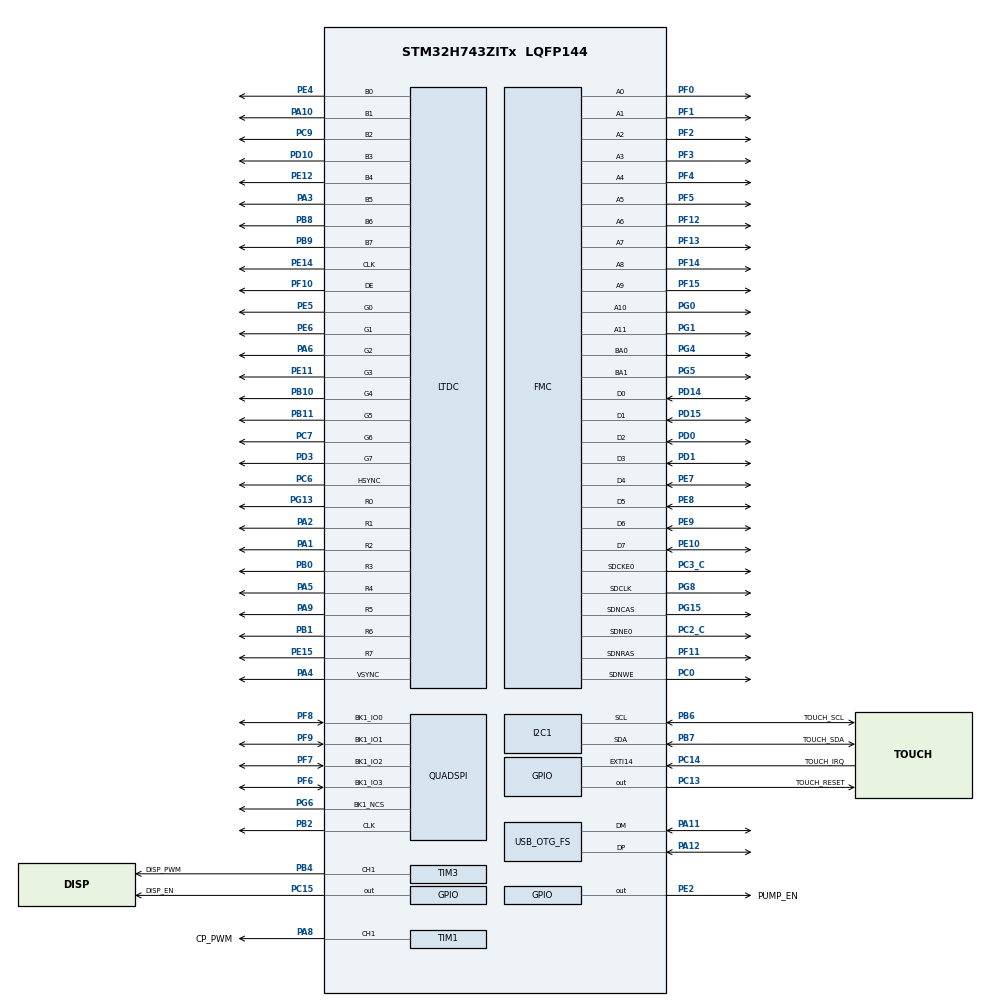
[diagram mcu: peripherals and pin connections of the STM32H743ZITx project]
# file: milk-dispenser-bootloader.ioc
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SH.FMC_D7_DA7.0=FMC_D7,sd-8b-d1
PE14.GPIO_Speed=GPIO_SPEED_FREQ_VERY_HIGH
FMC.RCDDelay1=2
FMC.SDClockPeriod1=FMC_SDRAM_CLOCK_PERIOD_2
SH.FMC_A0.0=FMC_A0,12b-sda1
QUADSPI.ClockPrescaler=7
PB10.Mode=RGB888
PG4.Signal=FMC_A14_BA0
PG8.Signal=FMC_SDCLK
I2C1.I2C_Rise_Time=14
PG0.Signal=FMC_A10
RCC.PLLFRACN=0
PB7.GPIO_FM7=SYSCFG_PMCR_I2C_PB7_FMP
PC3_C.Mode=SdramChipSelect1_1
FMC.LoadToActiveDelay1=2
CORTEX_M7.AccessPermission-Cortex_Memory_Protection_Unit_Region2_Settings=MPU_REGION_FULL_ACCESS
PB6.GPIO_Label=TOUCH_SCL
SH.FMC_D5_DA5.0=FMC_D5,sd-8b-d1
PA3.GPIO_Speed=GPIO_SPEED_FREQ_VERY_HIGH
PD3.GPIO_Speed=GPIO_SPEED_FREQ_VERY_HIGH
PG6.Mode=Single Bank 1
PG13.Signal=LTDC_R0
LTDC.Red=0
RCC.SYSCLKSource=RCC_SYSCLKSOURCE_PLLCLK
PB11.GPIO_Speed=GPIO_SPEED_FREQ_VERY_HIGH
SH.FMC_A15_BA1.0=FMC_BA1,FourSdramBanks1
PA14\ (JTCK/SWCLK).Signal=DEBUG_JTCK-SWCLK
CORTEX_M7.Enable-Cortex_Memory_Protection_Unit_Region0_Settings=MPU_REGION_ENABLE
CORTEX_M7.IsBufferable-Cortex_Memory_Protection_Unit_Region1_Settings=MPU_ACCESS_BUFFERABLE
PA4.Mode=RGB888
PF7.Signal=QUADSPI_BK1_IO2
SH.FMC_SDNWE.0=FMC_SDNWE,12b-sda1
PB6.Signal=I2C1_SCL
PC7.Signal=LTDC_G6
PB6.Mode=I2C
PD0.Signal=FMC_D2_DA2
USB_DEVICE.MSC_MEDIA_PACKET-MSC_FS=4096
PE5.Signal=LTDC_G0
QUADSPI.FlashSize=22
NVIC.EXTI15_10_IRQn=true\:2\:0\:true\:false\:true\:true\:true
PB2.Signal=QUADSPI_CLK
RCC.I2C123CLockSelection=RCC_I2C123CLKSOURCE_HSI
RCC.DIVM3=3
RCC.DIVM2=3
RCC.DIVM1=2
FATFS._USE_STRFUNC=0
FMC.SelfRefreshTime1=5
LTDC.PixelFormat_L0=LTDC_PIXEL_FORMAT_RGB565
TIM1.Channel-PWM\ Generation1\ CH1=TIM_CHANNEL_1
PB1.GPIO_Speed=GPIO_SPEED_FREQ_VERY_HIGH
PE9.Signal=FMC_D6_DA6
SH.FMC_A2.0=FMC_A2,12b-sda1
PC9.Mode=RGB888
FATFS._USE_MKFS=0
PE2.Signal=GPIO_Output
PF8.Mode=Single Bank 1
PA8.Signal=S_TIM1_CH1
PA14\ (JTCK/SWCLK).Mode=Serial_Wire
SH.FMC_D1_DA1.0=FMC_D1,sd-8b-d1
PF3.Signal=FMC_A3
PD3.Mode=RGB888
PE10.Signal=FMC_D7_DA7
LTDC.HSync=30
RCC.CKPERSourceSelection=RCC_CLKPSOURCE_CSI
CORTEX_M7.DisableExec-Cortex_Memory_Protection_Unit_Region1_Settings=MPU_INSTRUCTION_ACCESS_ENABLE
Mcu.Package=LQFP144
PB9.Signal=LTDC_B7
PB1.Signal=LTDC_R6
RCC.PLL3FRACN=0
PB6.GPIO_FM6=SYSCFG_PMCR_I2C_PB6_FMP
LTDC.Green=0
PA10.Signal=LTDC_B1
FMC.WriteRecoveryTime1=3
PE12.GPIO_Speed=GPIO_SPEED_FREQ_VERY_HIGH
SH.FMC_A1.0=FMC_A1,12b-sda1
FATFS._FS_MINIMIZE=0
SH.FMC_SDCLK.0=FMC_SDCLK,12b-sda1
LTDC.VSync=10
RCC.APB4Freq_Value=120000000
PF14.Signal=FMC_A8
CORTEX_M7.Enable-Cortex_Memory_Protection_Unit_Region1_Settings=MPU_REGION_ENABLE
FMC.RowCycleDelay2=6
PF10.Mode=RGB888
VP_USB_DEVICE_VS_USB_DEVICE_MSC_FS.Mode=MSC_FS
FMC.RowCycleDelay1=6
PA6.GPIO_Speed=GPIO_SPEED_FREQ_VERY_HIGH
FMC.ColumnBitsNumber1=FMC_SDRAM_COLUMN_BITS_NUM_10
PE6.GPIO_Speed=GPIO_SPEED_FREQ_VERY_HIGH
PH0-OSC_IN\ (PH0).Mode=HSE-External-Oscillator
PC6.GPIO_Speed=GPIO_SPEED_FREQ_VERY_HIGH
PA8.GPIO_Speed=GPIO_SPEED_FREQ_VERY_HIGH
PD15.Signal=FMC_D1_DA1
SH.FMC_D3_DA3.0=FMC_D3,sd-8b-d1
CORTEX_M7.IsBufferable-Cortex_Memory_Protection_Unit_Region0_Settings=MPU_ACCESS_NOT_BUFFERABLE
FATFS._MIN_SS=4096
PG6.GPIO_Speed=GPIO_SPEED_FREQ_VERY_HIGH
PA5.Mode=RGB888
PE12.Mode=RGB888
PB7.GPIO_PuPd=GPIO_PULLUP
SH.FMC_A4.0=FMC_A4,12b-sda1
I2C1.I2C_Fall_Time=14
PE11.GPIO_Speed=GPIO_SPEED_FREQ_VERY_HIGH
PG5.Signal=FMC_A15_BA1
PC13.Signal=GPIO_Output
PB6.GPIO_PuPd=GPIO_PULLUP
PD3.Signal=LTDC_G7
CORTEX_M7.IsCacheable-Cortex_Memory_Protection_Unit_Region0_Settings=MPU_ACCESS_NOT_CACHEABLE
PC6.Signal=LTDC_HSYNC
PD1.Signal=FMC_D3_DA3
PC0.Signal=FMC_SDNWE
LTDC.ImageWidth_L0=800
PD10.Signal=LTDC_B3
PA3.Mode=RGB888
SH.FMC_A3.0=FMC_A3,12b-sda1
PA8.GPIO_Label=CP_PWM
FMC.CASLatency1=FMC_SDRAM_CAS_LATENCY_2
TIM3.Pulse-PWM\ Generation1\ CH1=922
PB11.Mode=RGB888
PC6.Mode=RGB888
PA9.Signal=LTDC_R5
RCC.DIVN3=20
RCC.DIVN2=60
I2C1.Timing=0x108083B5
RCC.DIVN1=64
PC2_C.Mode=SdramChipSelect1_1
CORTEX_M7.BaseAddress-Cortex_Memory_Protection_Unit_Region0_Settings=0x60000000
PB10.Signal=LTDC_G4
RCC.USBCLockSelection=RCC_USBCLKSOURCE_HSI48
PA5.Signal=LTDC_R4
CORTEX_M7.Enable-Cortex_Memory_Protection_Unit_Region2_Settings=MPU_REGION_ENABLE
FMC.ReadBurst1=FMC_SDRAM_RBURST_ENABLE
SH.FMC_A6.0=FMC_A6,12b-sda1
FMC.ReadBurst2=FMC_SDRAM_RBURST_ENABLE
PA1.Mode=RGB888
PE14.Signal=LTDC_CLK
PE6.Mode=RGB888
PE15.Signal=LTDC_R7
PE8.Signal=FMC_D5_DA5
RCC.FMCCLockSelection=RCC_FMCCLKSOURCE_PLL2
CORTEX_M7.AccessPermission-Cortex_Memory_Protection_Unit_Region0_Settings=MPU_REGION_FULL_ACCESS
QUADSPI.FifoThreshold=5
PF13.Signal=FMC_A7
SH.FMC_SDNCAS.0=FMC_SDNCAS,12b-sda1
RCC.ProductRev=revV
PA4.Signal=LTDC_VSYNC
PC14-OSC32_IN\ (OSC32_IN).GPIO_Label=TOUCH_IRQ
SH.FMC_A5.0=FMC_A5,12b-sda1
LTDC.Alpha_L0=255
PA11.Signal=USB_OTG_FS_DM
ProjectManager.HeapSize=0x2000
PB1.Mode=RGB888
PF6.Mode=Single Bank 1
PF9.Signal=QUADSPI_BK1_IO1
CORTEX_M7.DisableExec-Cortex_Memory_Protection_Unit_Region2_Settings=MPU_INSTRUCTION_ACCESS_DISABLE
PC9.GPIO_Speed=GPIO_SPEED_FREQ_VERY_HIGH
NVIC.PriorityGroup=NVIC_PRIORITYGROUP_4
PE15.GPIO_Speed=GPIO_SPEED_FREQ_VERY_HIGH
PB8.Mode=RGB888
PF4.Signal=FMC_A4
PB4\ (NJTRST).GPIO_Label=DISP_PWM
PB6.GPIO_Speed=GPIO_SPEED_FREQ_VERY_HIGH
RCC.DIVR3=10
RCC.DIVR2=3
PB0.Signal=LTDC_R3
LTDC.Alpha0_L0=0
PA13\ (JTMS/SWDIO).Signal=DEBUG_JTMS-SWDIO
PE15.Mode=RGB888
PF6.GPIO_Speed=GPIO_SPEED_FREQ_VERY_HIGH
Mcu.Family=STM32H7
LTDC.BlendingFactor1_L0=LTDC_BLENDING_FACTOR1_PAxCA
PA6.Mode=RGB888
USB_DEVICE.CLASS_NAME_FS=MSC
SH.FMC_A8.0=FMC_A8,12b-sda1
RCC.CortexFreq_Value=480000000
PG6.Signal=QUADSPI_BK1_NCS
PB10.GPIO_Speed=GPIO_SPEED_FREQ_VERY_HIGH
RCC.HPRE=RCC_HCLK_DIV2
PH0-OSC_IN\ (PH0).Signal=RCC_OSC_IN
LTDC.HBP=46
PB2.GPIO_Speed=GPIO_SPEED_FREQ_VERY_HIGH
SH.FMC_NBL0.0=FMC_NBL0
PA2.GPIO_Speed=GPIO_SPEED_FREQ_VERY_HIGH
SH.FMC_D6_DA6.0=FMC_D6,sd-8b-d1
PA11.Mode=Device_Only
PF9.GPIO_Speed=GPIO_SPEED_FREQ_VERY_HIGH
PB4\ (NJTRST).GPIO_Speed=GPIO_SPEED_FREQ_HIGH
RCC.PLL2FRACN=0
SH.FMC_A14_BA0.0=FMC_BA0,FourSdramBanks1
TIM1.Pulse-PWM\ Generation1\ CH1=32768
SH.FMC_A11.0=FMC_A11,12b-sda1
PC13.GPIO_Label=TOUCH_RESET
PB11.Signal=LTDC_G5
LTDC.PCPolarity=LTDC_PCPOLARITY_IIPC
PG15.Signal=FMC_SDNCAS
ProjectManager.StackSize=0x4000
SH.FMC_A7.0=FMC_A7,12b-sda1
PA12.Signal=USB_OTG_FS_DP
PE11.Mode=RGB888
LTDC.Blue=0
FMC.BankMapConfig=FMC_SWAPBMAP_SDRAM_SRAM
RCC.HCLKFreq_Value=240000000
TIM3.Period=1025
LTDC.WindowX1_L0=800
PF12.Signal=FMC_A6
PD10.Mode=RGB888
PC2_C.Signal=FMC_SDNE0
SH.FMC_A10.0=FMC_A10,12b-sda1
TIM3.Channel-PWM\ Generation1\ CH1=TIM_CHANNEL_1
PH1-OSC_OUT\ (PH1).Mode=HSE-External-Oscillator
RCC.HSE_VALUE=30000000
CORTEX_M7.Size-Cortex_Memory_Protection_Unit_Region2_Settings=MPU_REGION_SIZE_4KB
FMC.ExitSelfRefreshDelay1=8
FMC.RPDelay2=2
FMC.RPDelay1=2
PA4.GPIO_Speed=GPIO_SPEED_FREQ_VERY_HIGH
SH.FMC_D2_DA2.0=FMC_D2,sd-8b-d1
LTDC.VBP=23
PF9.Mode=Single Bank 1
PF7.GPIO_Speed=GPIO_SPEED_FREQ_VERY_HIGH
PE4.GPIO_Speed=GPIO_SPEED_FREQ_VERY_HIGH
PF11.Signal=FMC_SDNRAS
PC13.GPIO_PuPd=GPIO_PULLUP
LTDC.HFP=4
PB7.Signal=I2C1_SDA
LTDC.BlendingFactor2_L0=LTDC_BLENDING_FACTOR2_PAxCA
PG13.Mode=RGB888
FMC.ReadPipeDelay1=FMC_SDRAM_RPIPE_DELAY_0
PE4.Mode=RGB888
SH.S_TIM3_CH1.0=TIM3_CH1,PWM Generation1 CH1
PD10.GPIO_Speed=GPIO_SPEED_FREQ_VERY_HIGH
SH.FMC_SDNRAS.0=FMC_SDNRAS,12b-sda1
LTDC.ActiveW=800
PE4.Signal=LTDC_B0
CORTEX_M7.DisableExec-Cortex_Memory_Protection_Unit_Region0_Settings=MPU_INSTRUCTION_ACCESS_DISABLE
RCC.APB3Freq_Value=120000000
PB7.GPIO_Label=TOUCH_SDA
PA6.Signal=LTDC_G2
SH.FMC_D0_DA0.0=FMC_D0,sd-8b-d1
RCC.D1PPRE=RCC_APB3_DIV2
CORTEX_M7.BaseAddress-Cortex_Memory_Protection_Unit_Region1_Settings=0x30000000
RCC.EnbaleCSS=true
NVIC.OTG_FS_IRQn=true\:0\:0\:false\:false\:true\:false\:true
USB_OTG_FS.VirtualMode=Device_Only
SH.FMC_A9.0=FMC_A9,12b-sda1
PF8.Signal=QUADSPI_BK1_IO0
SH.FMC_D4_DA4.0=FMC_D4,sd-8b-d1
PF5.Signal=FMC_A5
PA10.GPIO_Speed=GPIO_SPEED_FREQ_VERY_HIGH
CORTEX_M7.Size-Cortex_Memory_Protection_Unit_Region1_Settings=MPU_REGION_SIZE_256KB
FATFS._FS_LOCK=0
PB9.GPIO_Speed=GPIO_SPEED_FREQ_VERY_HIGH
PG13.GPIO_Speed=GPIO_SPEED_FREQ_VERY_HIGH
PF0.Signal=FMC_A0
PE7.Signal=FMC_D4_DA4
CORTEX_M7.IsShareable-Cortex_Memory_Protection_Unit_Region1_Settings=MPU_ACCESS_SHAREABLE
PE2.GPIO_Label=PUMP_EN
VP_TIM3_VS_ClockSourceINT.Mode=Internal
PC13.PinState=GPIO_PIN_RESET
PA3.Signal=LTDC_B5
PB7.GPIO_Speed=GPIO_SPEED_FREQ_VERY_HIGH
RCC.PLLSourceVirtual=RCC_PLLSOURCE_HSE
I2C1.Speed=100
QUADSPI.ChipSelectHighTime=QSPI_CS_HIGH_TIME_2_CYCLE
USB_DEVICE.VirtualMode-MSC_FS=Msc
CORTEX_M7.CPU_ICache=Enabled
LTDC.VFP=22
LTDC.WindowY1_L0=480
PA13\ (JTMS/SWDIO).Mode=Serial_Wire
PA10.Mode=RGB888
USB_DEVICE.VirtualModeFS=Msc_FS
PG1.Signal=FMC_A11
PF10.GPIO_Speed=GPIO_SPEED_FREQ_VERY_HIGH
RCC.D2PPRE2=RCC_APB2_DIV2
RCC.D2PPRE1=RCC_APB1_DIV2
CORTEX_M7.BaseAddress-Cortex_Memory_Protection_Unit_Region2_Settings=0x38800000
PH1-OSC_OUT\ (PH1).Signal=RCC_OSC_OUT
PB0.GPIO_Speed=GPIO_SPEED_FREQ_VERY_HIGH
PF7.Mode=Single Bank 1
CORTEX_M7.MPU_Control=MPU_PRIVILEGED_DEFAULT
PA9.Mode=RGB888
SH.S_TIM1_CH1.0=TIM1_CH1,PWM Generation1 CH1
PF6.Signal=QUADSPI_BK1_IO3
ProjectManager.TargetToolchain=STM32CubeIDE
PC15-OSC32_OUT\ (OSC32_OUT).Signal=GPIO_Output
PB9.Mode=RGB888
PF2.Signal=FMC_A2
RCC.USBFreq_Value=48000000
PE11.Signal=LTDC_G3
PA1.Signal=LTDC_R2
VP_FATFS_VS_Generic.Mode=User_defined
PB0.Mode=RGB888
board=custom
PC7.GPIO_Speed=GPIO_SPEED_FREQ_VERY_HIGH
FATFS._USE_FASTSEEK=0
RCC.APB2Freq_Value=120000000
LTDC.Layers=0
PF10.Signal=LTDC_DE
PA1.GPIO_Speed=GPIO_SPEED_FREQ_VERY_HIGH
PE14.Mode=RGB888
PE5.Mode=RGB888
CORTEX_M7.IsShareable-Cortex_Memory_Protection_Unit_Region0_Settings=MPU_ACCESS_SHAREABLE
RCC.ADCFreq_Value=300000000
PF15.Signal=FMC_A9
PF1.Signal=FMC_A1
PE6.Signal=LTDC_G1
Mcu.Name=STM32H743ZITx
PE0.Signal=FMC_NBL0
CORTEX_M7.Size-Cortex_Memory_Protection_Unit_Region0_Settings=MPU_REGION_SIZE_16MB
PE12.Signal=LTDC_B4
PA2.Signal=LTDC_R1
CORTEX_M7.AccessPermission-Cortex_Memory_Protection_Unit_Region1_Settings=MPU_REGION_FULL_ACCESS
CORTEX_M7.IsCacheable-Cortex_Memory_Protection_Unit_Region1_Settings=MPU_ACCESS_CACHEABLE
FATFS._MAX_SS=4096
PD14.Signal=FMC_D0_DA0
LTDC.WindowY0_L0=0
RCC.SYSCLKFreq_VALUE=480000000
PA12.Mode=Device_Only
LTDC.WindowX0_L0=0
PC14-OSC32_IN\ (OSC32_IN).Signal=GPXTI14
PC15-OSC32_OUT\ (OSC32_OUT).GPIO_Label=DISP_EN
PB2.Mode=Single Bank 1
PB7.Mode=I2C
PA5.GPIO_Speed=GPIO_SPEED_FREQ_VERY_HIGH
PC3_C.Signal=FMC_SDCKE0
PF8.GPIO_Speed=GPIO_SPEED_FREQ_VERY_HIGH
PE5.GPIO_Speed=GPIO_SPEED_FREQ_VERY_HIGH
PA2.Mode=RGB888
PA9.GPIO_Speed=GPIO_SPEED_FREQ_VERY_HIGH
PB8.Signal=LTDC_B6
RCC.D3PPRE=RCC_APB4_DIV2
FATFS._FS_READONLY=0
PC9.Signal=LTDC_B2
CORTEX_M7.CPU_DCache=Enabled
PC7.Mode=RGB888
RCC.APB1Freq_Value=120000000
PB8.GPIO_Speed=GPIO_SPEED_FREQ_VERY_HIGH
LTDC.ImageHeight_L0=480
PB4\ (NJTRST).Signal=S_TIM3_CH1

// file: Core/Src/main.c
/* USER CODE BEGIN Header */
/**
 ******************************************************************************
 * @file           : main.c
 * @brief          : Main program body
 ******************************************************************************
 * @attention
 *
 * <h2><center>&copy; Copyright (c) 2020 STMicroelectronics.
 * All rights reserved.</center></h2>
 *
 * This software component is licensed by ST under BSD 3-Clause license,
 * the "License"; You may not use this file except in compliance with the
 * License. You may obtain a copy of the License at:
 *                        opensource.org/licenses/BSD-3-Clause
 *
 ******************************************************************************
 */
/* USER CODE END Header */
#include "main.h"
#include "fatfs.h"
#include "i2c.h"
#include "ltdc.h"
#include "quadspi.h"
#include "tim.h"
#include "usb_device.h"
#include "gpio.h"
#include "fmc.h"

/* USER CODE BEGIN Includes */
#include <stdio.h>
#include <string.h>
#include <usbd_core.h>
#include "apploader.h"
#include "config.h"
#include "gt911.h"
#include "int_flash.h"
#include "log.h"
#include "pump.h"
#include "pump_power.h"
#include "sst26_flash.h"
#include "tft.h"
#include "terminal.h"

/* USER CODE END Includes */

/* USER CODE BEGIN PD */

#define MAGIC_CONST (uint32_t)0xA5B6C7E8
#define BackupRAM_BASE 0x38800000

/* USER CODE END PD */

/* USER CODE BEGIN PV */
extern USBD_HandleTypeDef hUsbDeviceFS;

extern uint32_t _aisr;
/* USER CODE END PV */

void SystemClock_Config(void);
static void MPU_Config(void);

/* USER CODE BEGIN 0 */

void printHex(const char *prefix, size_t length, uint8_t *buffer) {
	printf(prefix);
	for (size_t i = 0; i < length; i++) {
		if (i > 0) {
			if (i % 8 == 0) {
				printf("\n");
			} else {
				printf(" ");
			}
		}
		printf("0x%02X", buffer[i]);
	}
	printf("\n");
}

void enableBackupRAM() {
	HAL_PWREx_ConfigSupply(PWR_LDO_SUPPLY);
	HAL_PWR_EnableBkUpAccess();
	__HAL_RCC_BKPRAM_CLK_ENABLE();
	volatile uint32_t i = 0xffff;
	while (i != 0)
		i--;
}

/* USER CODE END 0 */

int main(void)
{
  /* USER CODE BEGIN 1 */
//	SCB->VTOR = (uint32_t)(&_aisr);
	SCB->VTOR = (uint32_t)(0x30000000);

	enableBackupRAM();

	__IO uint32_t *load_app_flag = (__IO uint32_t*)(BackupRAM_BASE);

	if (*load_app_flag == MAGIC_CONST) {
		*load_app_flag = (uint32_t) 0;
		AppLoader_load_application();
	}

	HAL_StatusTypeDef status = HAL_ERROR;

  /* USER CODE END 1 */

  /* MPU Configuration--------------------------------------------------------*/
  MPU_Config();

  /* Enable I-Cache---------------------------------------------------------*/
  SCB_EnableICache();

  /* Enable D-Cache---------------------------------------------------------*/
  SCB_EnableDCache();

  /* MCU Configuration--------------------------------------------------------*/

  /* Reset of all peripherals, Initializes the Flash interface and the Systick. */
  HAL_Init();

  /* Configure the system clock */
  SystemClock_Config();

  /* Initialize all configured peripherals */
  MX_GPIO_Init();
  MX_LTDC_Init();
  MX_TIM3_Init();
  MX_FMC_Init();
  MX_I2C1_Init();
  MX_TIM1_Init();
  MX_QUADSPI_Init();
  MX_USB_DEVICE_Init();
  MX_FATFS_Init();
  /* USER CODE BEGIN 2 */
	USBD_Stop(&hUsbDeviceFS);

	struct tTftFramebuffer framebuffer = TFT_init_framebuffer(&hltdc);
	terminal_init(&framebuffer);

	TFT_Set_brightness(256);

	HAL_GPIO_WritePin(DISP_EN_GPIO_Port, DISP_EN_Pin, GPIO_PIN_RESET);
	HAL_Delay(100);
	HAL_GPIO_WritePin(DISP_EN_GPIO_Port, DISP_EN_Pin, GPIO_PIN_SET);
	HAL_Delay(100);

	log_debug("Debug log");
	log_info("Info log");
	log_warn("Warn log");
	log_error("Error log");

	SST26_config.hqspi = &hqspi;
	SST26_config.timeout = 1000;

	status = SST26_init();
	if (status != HAL_OK) {
		log_error("Cannot initialize SST26 chip (external flash): 0x%02X",
				status);
		Error_Handler();
	}

	gt911_irq = false;
	if (GT911_Init() != HAL_OK) {
		printf("Touch init error. Reset the device\n");
		while (1)
			;
	}
	HAL_Delay(100);
	gt911_irq = true;

	FATFS FatFs;
	FRESULT FatResult;

	FatResult = f_mount(&FatFs, "", 1);
	if (FatResult != FR_OK) {
		log_error("f_mount error: 0x%02X", FatResult);
		Error_Handler();
	}
	struct tBootloaderConfig *config = BtldrConfig_Get();
	log_info("Touch the screen within %d seconds to activate flash drive",
			config->wait_for_flash_activation_confirmation_ms / 1000);
	uint32_t timeout_at = HAL_GetTick()
			+ config->wait_for_flash_activation_confirmation_ms;
	uint32_t printAt = HAL_GetTick() + 1000;
	while (HAL_GetTick() < timeout_at) {
		if (gt911.TouchCount > 0) {
			log_info("Activating flash drive in %d seconds",
					config->activate_flash_drive_timeout_ms / 1000);
			log_info("Reboot device when finished");
			HAL_Delay(config->activate_flash_drive_timeout_ms);
			f_mount(NULL, "", 1);
			USBD_Start(&hUsbDeviceFS);
			while (1)
				;
		}
		if (HAL_GetTick() > printAt) {
			printAt = HAL_GetTick() + 1000;
			log_info("%ld  ", (timeout_at - HAL_GetTick()) / 1000);
		}
	}
	log_info(
			"Bootloader was not activated. Running main application in %d seconds",
			config->activate_main_program_timeout_ms / 1000);
	HAL_Delay(config->activate_main_program_timeout_ms);

	log_info("This is run #%llu", BtldrConfig_incrementRuns());

	log_info("listing files in root");
	DIR dir;
	FatResult = f_opendir(&dir, "/");
	if (FatResult != FR_OK) {
		log_error("f_opendir error: 0x%02X", FatResult);
		Error_Handler();
	}

	FILINFO fileinfo;
	for (;;) {
		FatResult = f_readdir(&dir, &fileinfo);
		if (FatResult != FR_OK) {
			log_error("f_readdir error: 0x%02X", FatResult);
			Error_Handler();
		}
		if (strlen(fileinfo.fname) == 0) {
			break;
		}

		log_info("%c------ %-10lu %s", ((fileinfo.fattrib & AM_DIR) ? 'd':' '),
				fileinfo.fsize, fileinfo.fname);

	}

	f_closedir(&dir);

	log_info("Checking firmware");
	enum APL_RES aplres = AppLoader_check_firmware();
	switch (aplres) {
	case APPLOADER_OK:
	default:
		break;
	case APPLOADER_NO_FIRMWARE:
		log_error("Application firmware not found: APP.BIN");
		break;
	case APPLOADER_NO_CRC_FILE:
		log_error("Application checksum not found: APP.CRC");
		break;
	case APPLOADER_CRC_MISMATCH:
		log_error("Application checksum mismatch: APP.BIN <-> APP.CRC");
		break;
	}

	if (APPLOADER_OK == aplres) {
		log_info("New firmware check ok: code 0x%02X", aplres);
		log_info("Updating firmware...");
		if (!AppLoader_update_firmware()) {
			log_error("Firmware update failed");
			Error_Handler();
		}
		log_info("Verifying...");
		if (!AppLoader_verify_firmware()) {
			log_error("Firmware verification failed!");
			Error_Handler();
		}
	}

	// Deinit what we can
	f_mount(NULL, "", 1);

	log_info("Loading application...");
	*load_app_flag = MAGIC_CONST;
	HAL_Delay(1000);
	NVIC_SystemReset();

  /* USER CODE END 2 */

  /* Infinite loop */
  /* USER CODE BEGIN WHILE */
	while (1) {
		HAL_Delay(100000);
		printf("[%8ld] Hello, world!\n", HAL_GetTick());
    /* USER CODE END WHILE */

	}
}

void SystemClock_Config(void)
{
  RCC_OscInitTypeDef RCC_OscInitStruct = {0};
  RCC_ClkInitTypeDef RCC_ClkInitStruct = {0};

  /** Supply configuration update enable
  */
  HAL_PWREx_ConfigSupply(PWR_LDO_SUPPLY);
  /** Configure the main internal regulator output voltage
  */
  __HAL_PWR_VOLTAGESCALING_CONFIG(PWR_REGULATOR_VOLTAGE_SCALE0);

  while(!__HAL_PWR_GET_FLAG(PWR_FLAG_VOSRDY)) {}
  /** Macro to configure the PLL clock source
  */
  __HAL_RCC_PLL_PLLSOURCE_CONFIG(RCC_PLLSOURCE_HSE);
  /** Initializes the RCC Oscillators according to the specified parameters
  * in the RCC_OscInitTypeDef structure.
  */
  RCC_OscInitStruct.OscillatorType = RCC_OSCILLATORTYPE_HSI48|RCC_OSCILLATORTYPE_HSI
                              |RCC_OSCILLATORTYPE_HSE;
  RCC_OscInitStruct.HSEState = RCC_HSE_ON;
  RCC_OscInitStruct.HSIState = RCC_HSI_DIV1;
  RCC_OscInitStruct.HSICalibrationValue = RCC_HSICALIBRATION_DEFAULT;
  RCC_OscInitStruct.HSI48State = RCC_HSI48_ON;
  RCC_OscInitStruct.PLL.PLLState = RCC_PLL_ON;
  RCC_OscInitStruct.PLL.PLLSource = RCC_PLLSOURCE_HSE;
  RCC_OscInitStruct.PLL.PLLM = 2;
  RCC_OscInitStruct.PLL.PLLN = 64;
  RCC_OscInitStruct.PLL.PLLP = 2;
  RCC_OscInitStruct.PLL.PLLQ = 2;
  RCC_OscInitStruct.PLL.PLLR = 2;
  RCC_OscInitStruct.PLL.PLLRGE = RCC_PLL1VCIRANGE_3;
  RCC_OscInitStruct.PLL.PLLVCOSEL = RCC_PLL1VCOWIDE;
  RCC_OscInitStruct.PLL.PLLFRACN = 0;
  if (HAL_RCC_OscConfig(&RCC_OscInitStruct) != HAL_OK)
  {
    Error_Handler();
  }
  /** Initializes the CPU, AHB and APB buses clocks
  */
  RCC_ClkInitStruct.ClockType = RCC_CLOCKTYPE_HCLK|RCC_CLOCKTYPE_SYSCLK
                              |RCC_CLOCKTYPE_PCLK1|RCC_CLOCKTYPE_PCLK2
                              |RCC_CLOCKTYPE_D3PCLK1|RCC_CLOCKTYPE_D1PCLK1;
  RCC_ClkInitStruct.SYSCLKSource = RCC_SYSCLKSOURCE_PLLCLK;
  RCC_ClkInitStruct.SYSCLKDivider = RCC_SYSCLK_DIV1;
  RCC_ClkInitStruct.AHBCLKDivider = RCC_HCLK_DIV2;
  RCC_ClkInitStruct.APB3CLKDivider = RCC_APB3_DIV2;
  RCC_ClkInitStruct.APB1CLKDivider = RCC_APB1_DIV2;
  RCC_ClkInitStruct.APB2CLKDivider = RCC_APB2_DIV2;
  RCC_ClkInitStruct.APB4CLKDivider = RCC_APB4_DIV2;

  if (HAL_RCC_ClockConfig(&RCC_ClkInitStruct, FLASH_LATENCY_4) != HAL_OK)
  {
    Error_Handler();
  }
  /** Enables the Clock Security System
  */
  HAL_RCC_EnableCSS();
}

/* USER CODE BEGIN 4 */
void HAL_GPIO_EXTI_Callback(uint16_t GPIO_Pin) {
	if (GPIO_Pin == TOUCH_IRQ_Pin) {
		if (gt911_irq) {
			if (GT911_Scan(10) == HAL_ERROR) {
				GT911_Init();
				return;
			}
			GT911_CopyShadow();
		}
	}
}

/* USER CODE END 4 */

/* MPU Configuration */

void MPU_Config(void)
{
  MPU_Region_InitTypeDef MPU_InitStruct = {0};

  /* Disables the MPU */
  HAL_MPU_Disable();
  /** Initializes and configures the Region and the memory to be protected
  */
  MPU_InitStruct.Enable = MPU_REGION_ENABLE;
  MPU_InitStruct.Number = MPU_REGION_NUMBER0;
  MPU_InitStruct.BaseAddress = 0x60000000;
  MPU_InitStruct.Size = MPU_REGION_SIZE_16MB;
  MPU_InitStruct.SubRegionDisable = 0x0;
  MPU_InitStruct.TypeExtField = MPU_TEX_LEVEL0;
  MPU_InitStruct.AccessPermission = MPU_REGION_FULL_ACCESS;
  MPU_InitStruct.DisableExec = MPU_INSTRUCTION_ACCESS_DISABLE;
  MPU_InitStruct.IsShareable = MPU_ACCESS_SHAREABLE;
  MPU_InitStruct.IsCacheable = MPU_ACCESS_NOT_CACHEABLE;
  MPU_InitStruct.IsBufferable = MPU_ACCESS_NOT_BUFFERABLE;

  HAL_MPU_ConfigRegion(&MPU_InitStruct);
  /** Initializes and configures the Region and the memory to be protected
  */
  MPU_InitStruct.Number = MPU_REGION_NUMBER1;
  MPU_InitStruct.BaseAddress = 0x30000000;
  MPU_InitStruct.Size = MPU_REGION_SIZE_256KB;
  MPU_InitStruct.DisableExec = MPU_INSTRUCTION_ACCESS_ENABLE;
  MPU_InitStruct.IsCacheable = MPU_ACCESS_CACHEABLE;
  MPU_InitStruct.IsBufferable = MPU_ACCESS_BUFFERABLE;

  HAL_MPU_ConfigRegion(&MPU_InitStruct);
  /** Initializes and configures the Region and the memory to be protected
  */
  MPU_InitStruct.Number = MPU_REGION_NUMBER2;
  MPU_InitStruct.BaseAddress = 0x38800000;
  MPU_InitStruct.Size = MPU_REGION_SIZE_4KB;
  MPU_InitStruct.DisableExec = MPU_INSTRUCTION_ACCESS_DISABLE;
  MPU_InitStruct.IsShareable = MPU_ACCESS_NOT_SHAREABLE;
  MPU_InitStruct.IsCacheable = MPU_ACCESS_NOT_CACHEABLE;
  MPU_InitStruct.IsBufferable = MPU_ACCESS_NOT_BUFFERABLE;

  HAL_MPU_ConfigRegion(&MPU_InitStruct);
  /* Enables the MPU */
  HAL_MPU_Enable(MPU_PRIVILEGED_DEFAULT);

}

void Error_Handler(void)
{
  /* USER CODE BEGIN Error_Handler_Debug */
	/* User can add his own implementation to report the HAL error return state */
	log_error("Error handler");
	__disable_irq();
	while (1) {
	}
  /* USER CODE END Error_Handler_Debug */
}

#ifdef  USE_FULL_ASSERT
/**
  * @brief  Reports the name of the source file and the source line number
  *         where the assert_param error has occurred.
  * @param  file: pointer to the source file name
  * @param  line: assert_param error line source number
  * @retval None
  */
void assert_failed(uint8_t *file, uint32_t line)
{
  /* USER CODE BEGIN 6 */
	/* User can add his own implementation to report the file name and line number,
	 ex: printf("Wrong parameters value: file %s on line %d\r\n", file, line) */
	log_error("Wrong parameters value: file %s on line %d\r\n", file, line);
  /* USER CODE END 6 */
}
#endif /* USE_FULL_ASSERT */

/************************ (C) COPYRIGHT STMicroelectronics *****END OF FILE****/
